CM_ "AUTOGENERATED FILE, DO NOT EDIT";

CM_ "Imported file _wuling_almazrs.dbc starts here ";
VERSION ""

NS_ :

BS_:

BU_:

BO_ 840 EBCMWheelSpdFront: 6 K17_EBCM
 SG_ FLWheelSpd : 6|15@0+ (0.0311,0) [0|255] "km/h" NEO
 SG_ FRWheelSpd : 22|15@0+ (0.0622,0) [0|255] "km/h" NEO

BO_ 842 EBCMWheelSpdRear: 6 K17_EBCM
 SG_ RLWheelSpd : 6|15@0+ (0.0311,0) [0|255] "km/h" NEO
 SG_ RRWheelSpd : 22|15@0+ (0.0622,0) [0|255] "km/h" NEO

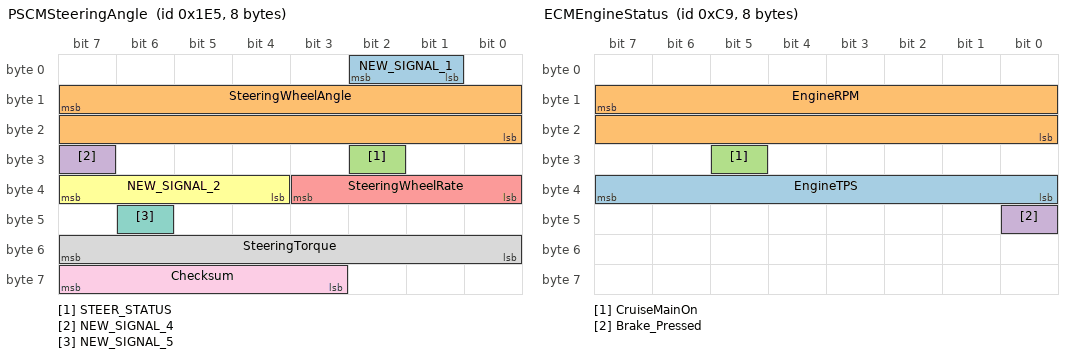
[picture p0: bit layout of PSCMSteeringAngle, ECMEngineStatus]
BO_ 485 PSCMSteeringAngle: 8 K43_PSCM
 SG_ NEW_SIGNAL_1 : 2|2@0+ (1,0) [0|1] "" XXX
 SG_ SteeringWheelAngle : 15|16@0- (-0.0625,0) [-2047|2047] "deg" NEO
 SG_ STEER_STATUS : 26|1@0+ (1,0) [0|1] "" XXX
 SG_ NEW_SIGNAL_4 : 31|1@0+ (1,0) [0|1] "" XXX
 SG_ SteeringWheelRate : 35|4@0- (1,0) [-2047|2047] "deg/s" NEO
 SG_ NEW_SIGNAL_2 : 36|4@1+ (1,0) [0|15] "" XXX
 SG_ NEW_SIGNAL_5 : 46|1@0+ (1,0) [0|1] "" XXX
 SG_ SteeringTorque : 55|8@0- (-1,0) [-2047|2047] "" XXX
 SG_ Checksum : 59|5@1- (1,0) [0|255] "" XXX

BO_ 201 ECMEngineStatus: 8 K20_ECM
 SG_ EngineTPS : 39|8@0+ (0.392156863,0) [0|100.000000065] "%" NEO
 SG_ EngineRPM : 15|16@0+ (0.25,0) [0|0] "RPM" NEO
 SG_ CruiseMainOn : 29|1@0+ (1,0) [0|1] "" NEO
 SG_ Brake_Pressed : 40|1@0+ (1,0) [0|1] "" NEO

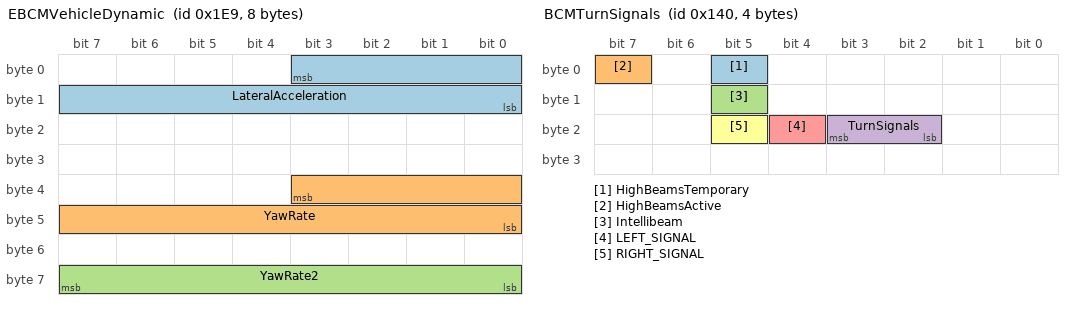
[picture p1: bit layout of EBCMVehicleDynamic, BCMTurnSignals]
BO_ 489 EBCMVehicleDynamic: 8 K17_EBCM
 SG_ LateralAcceleration : 3|12@0- (0.161,0) [-2047|2047] "m/s2" NEO
 SG_ YawRate : 35|12@0- (0.625,0) [0|1] "" NEO
 SG_ YawRate2 : 63|8@0- (0.0625,0) [-2047|2047] "grad/s" NEO

BO_ 320 BCMTurnSignals: 4 K9_BCM
 SG_ HighBeamsTemporary : 5|1@0+ (1,0) [0|1] "" NEO
 SG_ HighBeamsActive : 7|1@0+ (1,0) [0|1] "" NEO
 SG_ Intellibeam : 13|1@0+ (1,0) [0|1] "" NEO
 SG_ TurnSignals : 19|2@0+ (1,0) [0|0] "" NEO
 SG_ LEFT_SIGNAL : 20|1@0+ (1,0) [0|1] "" XXX
 SG_ RIGHT_SIGNAL : 21|1@0+ (1,0) [0|1] "" XXX

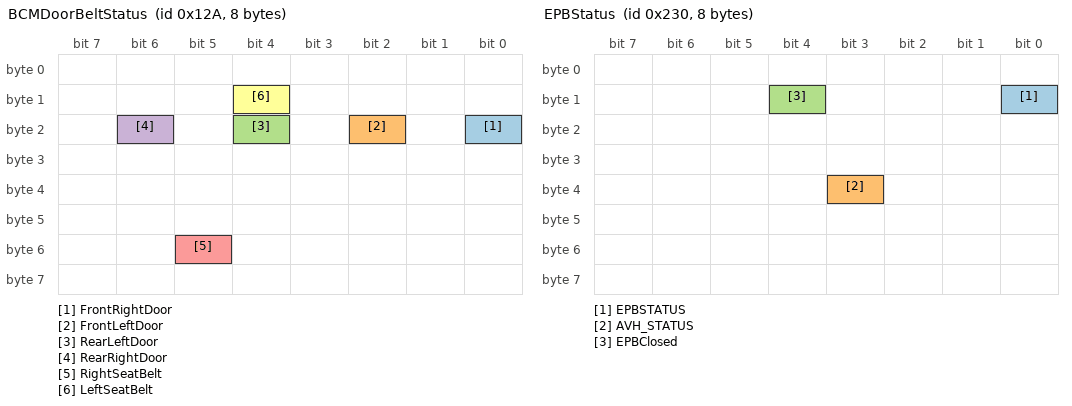
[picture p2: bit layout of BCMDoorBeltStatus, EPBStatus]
BO_ 298 BCMDoorBeltStatus: 8 K9_BCM
 SG_ FrontRightDoor : 16|1@0+ (1,0) [0|1] "" NEO
 SG_ FrontLeftDoor : 18|1@0+ (1,0) [0|0] "" NEO
 SG_ RearLeftDoor : 20|1@0+ (1,0) [0|0] "" NEO
 SG_ RearRightDoor : 22|1@0+ (1,0) [0|0] "" NEO
 SG_ RightSeatBelt : 53|1@0+ (1,0) [0|0] "" NEO
 SG_ LeftSeatBelt : 12|1@0+ (1,0) [0|0] "" NEO

BO_ 560 EPBStatus: 8 EPB
 SG_ EPBSTATUS : 8|1@0+ (1,0) [0|1] "" XXX
 SG_ AVH_STATUS : 35|1@0+ (1,0) [0|1] "" XXX
 SG_ EPBClosed : 12|1@0+ (1,0) [0|1] "" NEO

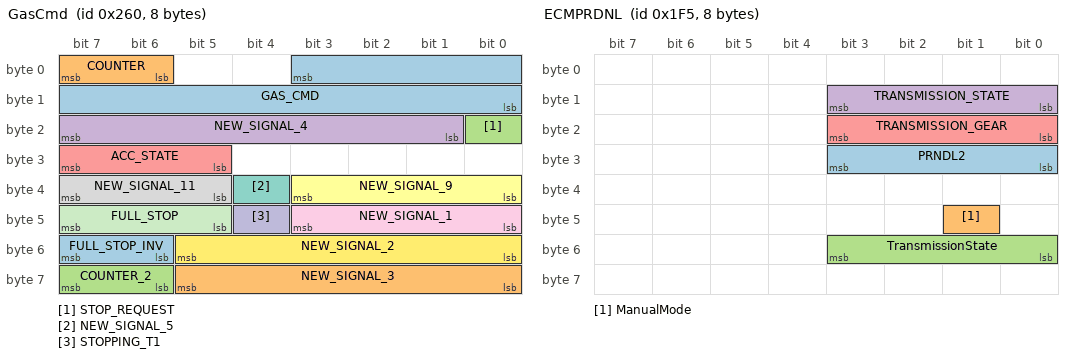
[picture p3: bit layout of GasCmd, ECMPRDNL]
BO_ 608 GasCmd: 8 XXX
 SG_ GAS_CMD : 3|12@0- (1,0) [0|255] "" XXX
 SG_ COUNTER : 7|2@0+ (1,0) [0|3] "" XXX
 SG_ STOP_REQUEST : 16|1@0+ (1,0) [0|1] "" XXX
 SG_ NEW_SIGNAL_4 : 17|7@1+ (1,0) [0|127] "" XXX
 SG_ ACC_STATE : 29|3@1+ (1,0) [0|7] "" XXX
 SG_ NEW_SIGNAL_9 : 32|4@1- (1,0) [0|15] "" XXX
 SG_ NEW_SIGNAL_5 : 36|1@0+ (1,0) [0|1] "" XXX
 SG_ NEW_SIGNAL_11 : 37|3@1+ (1,0) [0|7] "" XXX
 SG_ NEW_SIGNAL_1 : 43|4@0- (1,0) [0|65535] "" XXX
 SG_ STOPPING_T1 : 44|1@0+ (1,0) [0|1] "" XXX
 SG_ FULL_STOP : 45|3@1+ (1,0) [0|7] "" XXX
 SG_ NEW_SIGNAL_2 : 53|6@0- (1,0) [0|255] "" XXX
 SG_ FULL_STOP_INV : 54|2@1+ (1,0) [0|3] "" XXX
 SG_ NEW_SIGNAL_3 : 61|6@0- (1,0) [0|63] "" XXX
 SG_ COUNTER_2 : 63|2@0+ (1,0) [0|3] "" XXX

BO_ 880 ASCMActiveCruiseControlStatus: 8 K124_ASCM
 SG_ ACCGapLevel : 0|3@1+ (1,0) [0|7] "" XXX
 SG_ COUNTER_1 : 7|2@0+ (1,0) [0|3] "" XXX
 SG_ ACCAlwaysOne2 : 13|2@0+ (1,0) [0|0] "" Vector__XXX
 SG_ ACCAlwaysOne : 15|1@0+ (1,0) [0|0] "" Vector__XXX
 SG_ ACCCmdActive : 23|1@0+ (1,0) [0|0] "" NEO
 SG_ ACCSpeedSetpoint : 31|8@0- (1,0) [0|200] "km/h" NEO
 SG_ ACCResumeAlert : 32|1@0+ (1,0) [0|1] "" XXX
 SG_ ACCResumeButton : 33|1@0+ (1,0) [0|1] "" XXX
 SG_ ACCBUTTON : 35|2@0+ (1,0) [0|1] "" XXX
 SG_ NEW_SIGNAL_1 : 38|3@0+ (1,0) [0|1] "" XXX
 SG_ FCWAlert : 41|2@0+ (1,0) [0|3] "" XXX
 SG_ GAPDisplay : 46|1@0+ (1,0) [0|1] "" XXX
 SG_ NEW_SIGNAL_3 : 48|1@0+ (1,0) [0|1] "" XXX
 SG_ FCW : 49|1@0+ (1,0) [0|1] "" XXX
 SG_ ACCSTATE : 53|1@0+ (1,0) [0|1] "" XXX
 SG_ ACCSTATE2 : 54|1@0+ (1,0) [0|0] "" Vector__XXX
 SG_ NEW_SIGNAL_2 : 55|1@0+ (1,0) [0|1] "" XXX
 SG_ SET_ME_X16 : 56|4@1- (1,0) [0|63] "" XXX
 SG_ NEW_SIGNAL_4 : 60|2@1+ (1,0) [0|3] "" XXX
 SG_ COUNTER_2 : 63|2@0+ (1,0) [0|3] "" XXX

BO_ 1001 ECMVehicleSpeed: 8 K20_ECM
 SG_ VehicleSpeed : 7|16@0+ (0.01,0) [0|0] "mph" NEO

BO_ 1033 ASCMKeepAlive: 7 NEO
 SG_ ASCMKeepAliveAllZero : 7|56@0+ (1,0) [0|0] "" NEO

BO_ 501 ECMPRDNL: 8 K20_ECM
 SG_ PRNDL2 : 27|4@0+ (1,0) [0|255] "" NEO
 SG_ ManualMode : 41|1@0+ (1,0) [0|1] "" NEO
 SG_ TransmissionState : 48|4@1+ (1,0) [0|7] "" NEO
 SG_ TRANSMISSION_STATE : 8|4@1+ (1,0) [0|15] "" NEO
 SG_ TRANSMISSION_GEAR : 16|4@1+ (1,0) [0|15] "" NEO

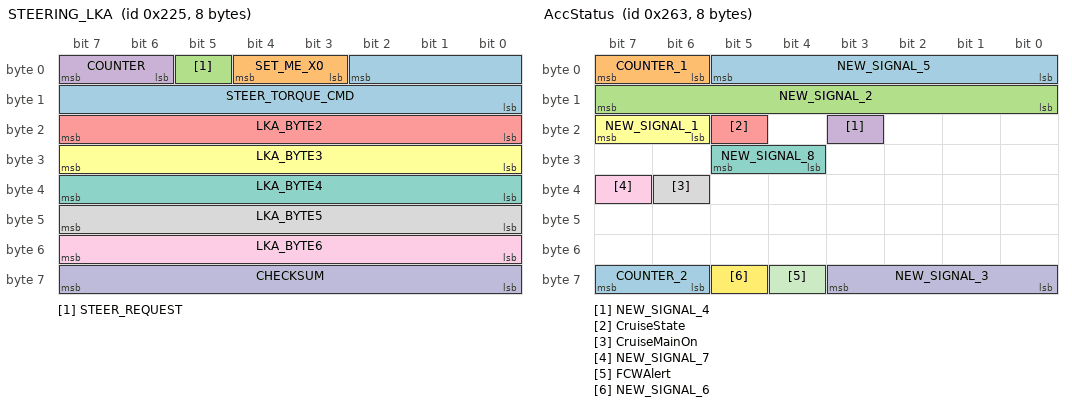
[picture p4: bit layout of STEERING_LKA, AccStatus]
BO_ 549 STEERING_LKA: 8 XXX
 SG_ STEER_TORQUE_CMD : 2|11@0- (1,0) [0|0] "" XXX
 SG_ SET_ME_X0 : 3|2@1+ (1,0) [0|3] "" XXX
 SG_ STEER_REQUEST : 5|1@0+ (1,0) [0|1] "" XXX
 SG_ COUNTER : 7|2@0+ (1,0) [0|7] "" XXX
 SG_ LKA_BYTE2 : 16|8@1+ (1,0) [0|255] "" XXX
 SG_ LKA_BYTE3 : 24|8@1+ (1,0) [0|255] "" XXX
 SG_ LKA_BYTE4 : 32|8@1+ (1,0) [0|255] "" XXX
 SG_ LKA_BYTE5 : 40|8@1+ (1,0) [0|255] "" XXX
 SG_ LKA_BYTE6 : 48|8@1+ (1,0) [0|255] "" XXX
 SG_ CHECKSUM : 63|8@0+ (1,0) [0|255] "" XXX

BO_ 883 LkasHud: 8 K20_ECM
 SG_ ALERT : 0|1@0+ (1,0) [0|1] "" XXX
 SG_ LKA_ACTIVE : 1|1@0+ (1,0) [0|1] "" NEO
 SG_ LEAD_FOLLOW_1 : 2|1@0+ (1,0) [0|1] "" XXX
 SG_ UNKNOWN_1 : 3|3@1+ (1,0) [0|7] "" XXX
 SG_ UNKNOWN_2 : 24|8@1+ (1,0) [0|255] "" XXX
 SG_ UNKNOWN_3 : 14|1@0+ (1,0) [0|1] "" XXX
 SG_ LKAS_STATE : 10|1@0+ (1,0) [0|1] "" NEO
 SG_ LEAD_FOLLOW_2 : 11|1@0+ (1,0) [0|1] "" XXX
 SG_ LKA_LINE : 13|2@0+ (1,0) [0|3] "" XXX
 SG_ LKA_LINE_2 : 60|2@1+ (1,0) [0|3] "" XXX
 SG_ ALERT_DEPART1 : 15|1@0+ (1,0) [0|1] "" XXX
 SG_ HUD_ALERT : 16|3@1+ (1,0) [0|7] "" XXX
 SG_ NEW_SIGNAL_1 : 8|2@1+ (1,0) [0|3] "" XXX
 SG_ NEW_SIGNAL_4 : 19|1@0+ (1,0) [0|1] "" XXX
 SG_ NEW_SIGNAL_2 : 20|1@0+ (1,0) [0|1] "" XXX
 SG_ NEW_SIGNAL_3 : 21|3@1+ (1,0) [0|7] "" XXX
 SG_ NEW_SIGNAL_8 : 32|8@1+ (1,0) [0|255] "" XXX
 SG_ NEW_SIGNAL_7 : 40|8@1+ (1,0) [0|255] "" XXX
 SG_ NEW_SIGNAL_6 : 48|8@1+ (1,0) [0|255] "" XXX
 SG_ STEER_WARNING : 56|4@1+ (1,0) [0|15] "" XXX
 SG_ COUNTER_1 : 6|2@1+ (1,0) [0|3] "" XXX
 SG_ COUNTER_2 : 62|2@1+ (1,0) [0|3] "" XXX

BO_ 611 AccStatus: 8 XXX
 SG_ NEW_SIGNAL_5 : 0|6@1+ (1,0) [0|63] "" XXX
 SG_ COUNTER_1 : 6|2@1+ (1,0) [0|3] "" XXX
 SG_ NEW_SIGNAL_2 : 8|8@1+ (1,0) [0|255] "" XXX
 SG_ NEW_SIGNAL_4 : 19|1@0+ (1,0) [0|1] "" XXX
 SG_ CruiseState : 21|1@0+ (1,0) [0|1] "" XXX
 SG_ NEW_SIGNAL_1 : 22|2@1+ (1,0) [0|3] "" XXX
 SG_ NEW_SIGNAL_8 : 28|2@1+ (1,0) [0|3] "" XXX
 SG_ CruiseMainOn : 38|1@0+ (1,0) [0|1] "" XXX
 SG_ NEW_SIGNAL_7 : 39|1@0+ (1,0) [0|1] "" XXX
 SG_ NEW_SIGNAL_3 : 56|4@1+ (1,0) [0|63] "" XXX
 SG_ FCWAlert : 60|1@1+ (1,0) [0|3] "" XXX
 SG_ NEW_SIGNAL_6 : 61|1@0+ (1,0) [0|1] "" XXX
 SG_ COUNTER_2 : 62|2@1+ (1,0) [0|3] "" XXX

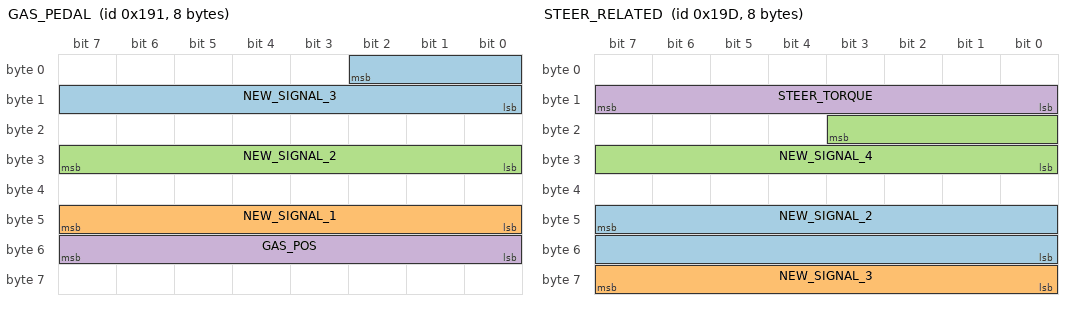
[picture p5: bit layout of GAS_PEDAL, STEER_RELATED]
BO_ 401 GAS_PEDAL: 8 XXX
 SG_ NEW_SIGNAL_3 : 2|11@0+ (1,0) [0|2047] "" XXX
 SG_ NEW_SIGNAL_1 : 40|8@1+ (1,0) [0|255] "" XXX
 SG_ NEW_SIGNAL_2 : 31|8@0+ (1,0) [0|255] "" XXX
 SG_ GAS_POS : 55|8@0+ (1,0) [0|255] "" XXX

BO_ 413 STEER_RELATED: 8 XXX
 SG_ NEW_SIGNAL_2 : 47|16@0+ (1,0) [0|65535] "" XXX
 SG_ NEW_SIGNAL_3 : 56|8@1+ (1,0) [0|255] "" XXX
 SG_ NEW_SIGNAL_4 : 19|12@0+ (1,0) [0|4095] "" XXX
 SG_ STEER_TORQUE : 15|8@0- (-1,0) [-255|255] "" XXX

BO_ 617 BRAKE_MODULE: 8 XXX
 SG_ NEW_SIGNAL_3 : 56|6@1+ (1,0) [0|63] "" XXX
 SG_ NEW_SIGNAL_4 : 55|2@0+ (1,0) [0|3] "" XXX
 SG_ BRAKE_PRESSED : 37|1@0+ (1,0) [0|1] "" XXX
 SG_ NEW_SIGNAL_7 : 32|4@1+ (1,0) [0|15] "" XXX
 SG_ ENABLE : 21|1@0+ (1,0) [0|1] "" XXX
 SG_ AEB : 19|1@0+ (1,0) [0|1] "" XXX
 SG_ COUNTER : 7|2@0+ (1,0) [0|3] "" XXX
 SG_ COUNTER_2 : 63|2@0+ (1,0) [0|3] "" XXX
 SG_ NEW_SIGNAL_6 : 5|1@0+ (1,0) [0|1] "" XXX
 SG_ NEW_SIGNAL_2 : 0|3@1+ (1,0) [0|7] "" XXX
 SG_ NEW_SIGNAL_5 : 16|5@1+ (1,0) [0|31] "" XXX
 SG_ NEW_SIGNAL_8 : 24|8@1+ (1,0) [0|255] "" XXX
 SG_ BRAKE_CMD : 15|8@0+ (1,0) [0|2047] "" XXX
 SG_ BRAKE_CMD_2 : 40|8@1+ (1,0) [0|255] "" XXX

BO_ 225 BCMDoorBelt: 8 XXX
 SG_ RIGHTSEATBEALT : 11|1@0+ (1,0) [0|1] "" XXX
 SG_ LEFTSEATBEALT : 23|1@0+ (1,0) [0|1] "" XXX

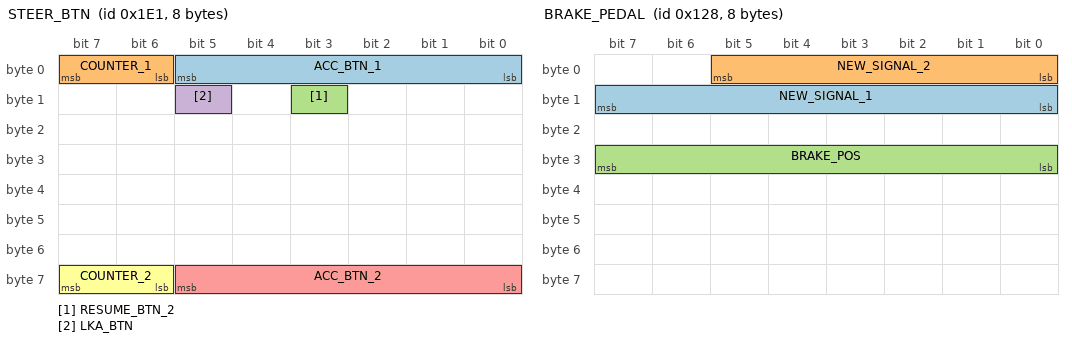
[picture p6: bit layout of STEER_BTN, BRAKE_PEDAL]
BO_ 481 STEER_BTN: 8 XXX
 SG_ ACC_BTN_1 : 0|6@1+ (1,0) [0|15] "" XXX
 SG_ COUNTER_1 : 7|2@0+ (1,0) [0|3] "" XXX
 SG_ RESUME_BTN_2 : 11|1@0+ (1,0) [0|1] "" XXX
 SG_ LKA_BTN : 13|1@0+ (1,0) [0|1] "" XXX
 SG_ ACC_BTN_2 : 61|6@0+ (1,0) [0|15] "" XXX
 SG_ COUNTER_2 : 63|2@0+ (1,0) [0|3] "" XXX

BO_ 296 BRAKE_PEDAL: 8 XXX
 SG_ NEW_SIGNAL_1 : 15|8@0+ (1,0) [0|255] "" XXX
 SG_ NEW_SIGNAL_2 : 0|6@1+ (1,0) [0|255] "" XXX
 SG_ BRAKE_POS : 24|8@1- (1,0) [-255|255] "" XXX

BO_ 1065 STEER_STATUS: 8 XXX
 SG_ STEER_STATUS : 13|3@1+ (1,0) [0|7] "" XXX

BO_ 177 BSM_SIGNAL: 8 XXX
 SG_ SIGNAL_1 : 0|2@1+ (1,0) [0|255] "" XXX
 SG_ SIGNAL_2 : 8|2@1+ (1,0) [0|3] "" XXX

VAL_ 501 TRANSMISSION_STATE 1 "D" 2 "D" 3 "D" 4 "D" 5 "D" 6 "D" 7 "D" 8 "D" 13 "N" 14 "R" 15 "P";
